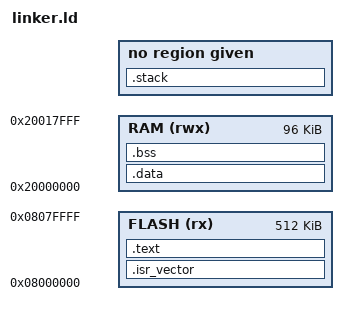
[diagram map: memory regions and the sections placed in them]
ENTRY(Reset_Handler)

MEMORY
{
  FLASH (rx)  : ORIGIN = 0x08000000, LENGTH = 512K
  RAM   (rwx) : ORIGIN = 0x20000000, LENGTH = 96K
}

SECTIONS
{
  .isr_vector : {
    KEEP(*(.isr_vector))
  } > FLASH

  .text : {
    *(.text*)
    *(.rodata*)
    _etext = .;
  } > FLASH

  _sidata = LOADADDR(.data);

  .data : AT(_sidata) {
    _sdata = .;
    *(.data*)
    _edata = .;
  } > RAM

  .bss : {
    _sbss = .;
    *(.bss*)
    *(COMMON)
    _ebss = .;
  } > RAM

  .stack (COPY):
  {
    . = ALIGN(8);
    _estack = ORIGIN(RAM) + LENGTH(RAM);
  }
}
